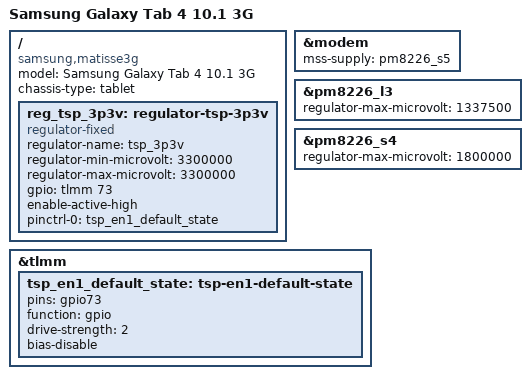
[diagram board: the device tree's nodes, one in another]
// SPDX-License-Identifier: BSD-3-Clause
/dts-v1/;
#include "qcom-msm8226.dtsi"
#include "qcom-msm8226-samsung-matisse-common.dtsi"

/ {
	model = "Samsung Galaxy Tab 4 10.1 3G";
	compatible = "samsung,matisse3g", "qcom,msm8226";
	chassis-type = "tablet";

	reg_tsp_3p3v: regulator-tsp-3p3v {
		compatible = "regulator-fixed";
		regulator-name = "tsp_3p3v";
		regulator-min-microvolt = <3300000>;
		regulator-max-microvolt = <3300000>;
		gpio = <&tlmm 73 GPIO_ACTIVE_HIGH>;
		enable-active-high;
		pinctrl-names = "default";
		pinctrl-0 = <&tsp_en1_default_state>;
	};
};

&modem { mss-supply = <&pm8226_s5>; };
&pm8226_l3 { regulator-max-microvolt = <1337500>; };
&pm8226_s4 { regulator-max-microvolt = <1800000>; };

&tlmm {
	tsp_en1_default_state: tsp-en1-default-state {
		pins = "gpio73"; function = "gpio";
		drive-strength = <2>; bias-disable;
	};
};
